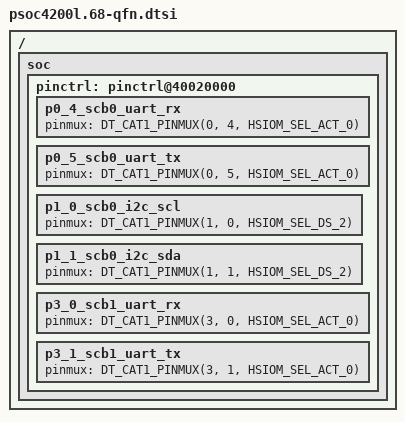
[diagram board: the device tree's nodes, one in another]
/*
 * Copyright (c) 2025 PSoC 4200L Zephyr Port
 * SPDX-License-Identifier: Apache-2.0
 *
 * Minimal pin configuration for CY8C4248LTI-L475 (68-QFN package).
 * HSIOM function assignments from PSoC 4200L datasheet pinout table.
 *
 * PSoC 4200L SCB HSIOM mapping:
 *   SCB0: HSIOM_SEL_ACT_0 (P0.4=RX, P0.5=TX, P1.0=SCL, P1.1=SDA)
 *   SCB1: HSIOM_SEL_ACT_0 (P3.0=RX, P3.1=TX)
 *   SCB2: HSIOM_SEL_ACT_0 (P0.4=RX, P0.5=TX via alternate)
 *   SCB3: HSIOM_SEL_ACT_0 (P6.0=RX, P6.1=TX)
 *
 * NOTE: HSIOM_SEL values need verification against PSoC 4200L Register TRM.
 * Using HSIOM_SEL_ACT_0 as placeholder; actual values may differ per pin/SCB.
 */

#include <zephyr/dt-bindings/gpio/gpio.h>
#include <zephyr/dt-bindings/pinctrl/ifx_cat1-pinctrl.h>
#include "psoc4200l.dtsi"

/ {
	soc {
		pinctrl: pinctrl@40020000 {
			/* SCB0 UART: P0.4=RX, P0.5=TX */
			/omit-if-no-ref/ p0_4_scb0_uart_rx: p0_4_scb0_uart_rx {
				pinmux = <DT_CAT1_PINMUX(0, 4, HSIOM_SEL_ACT_0)>;
			};

			/omit-if-no-ref/ p0_5_scb0_uart_tx: p0_5_scb0_uart_tx {
				pinmux = <DT_CAT1_PINMUX(0, 5, HSIOM_SEL_ACT_0)>;
			};

			/* SCB0 I2C: P1.0=SCL, P1.1=SDA */
			/omit-if-no-ref/ p1_0_scb0_i2c_scl: p1_0_scb0_i2c_scl {
				pinmux = <DT_CAT1_PINMUX(1, 0, HSIOM_SEL_DS_2)>;
			};

			/omit-if-no-ref/ p1_1_scb0_i2c_sda: p1_1_scb0_i2c_sda {
				pinmux = <DT_CAT1_PINMUX(1, 1, HSIOM_SEL_DS_2)>;
			};

			/* SCB1 UART: P3.0=RX, P3.1=TX */
			/omit-if-no-ref/ p3_0_scb1_uart_rx: p3_0_scb1_uart_rx {
				pinmux = <DT_CAT1_PINMUX(3, 0, HSIOM_SEL_ACT_0)>;
			};

			/omit-if-no-ref/ p3_1_scb1_uart_tx: p3_1_scb1_uart_tx {
				pinmux = <DT_CAT1_PINMUX(3, 1, HSIOM_SEL_ACT_0)>;
			};
		};
	};
};
